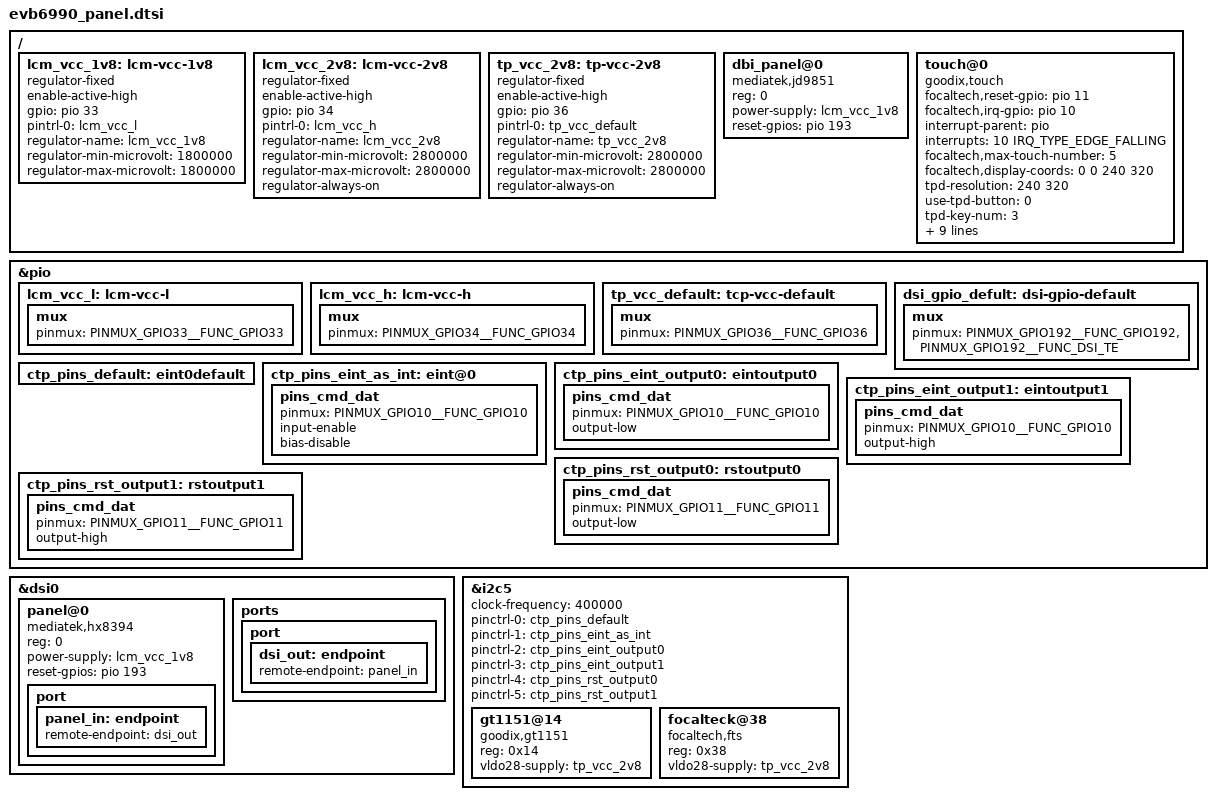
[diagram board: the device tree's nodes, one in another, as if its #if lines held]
/*evb6990_panel.dtsi*/

/ {
	lcm_vcc_1v8: lcm-vcc-1v8 {
        	compatible = "regulator-fixed";
        	enable-active-high;
        	gpio = <&pio 33 GPIO_ACTIVE_HIGH>;
        	pinctrl-names = "default";
        	pintrl-0 = <&lcm_vcc_l>;
        	regulator-name = "lcm_vcc_1v8";
        	regulator-min-microvolt = <1800000>;
        	regulator-max-microvolt = <1800000>;
	};
	
	lcm_vcc_2v8: lcm-vcc-2v8 {
                compatible = "regulator-fixed";
                enable-active-high;
                gpio = <&pio 34 GPIO_ACTIVE_HIGH>;
                pinctrl-names = "default";
                pintrl-0 = <&lcm_vcc_h>;
                regulator-name = "lcm_vcc_2v8";
                regulator-min-microvolt = <2800000>;
                regulator-max-microvolt = <2800000>;
		regulator-always-on;
        };

	tp_vcc_2v8: tp-vcc-2v8 {
                compatible = "regulator-fixed";
                enable-active-high;
                gpio = <&pio 36 GPIO_ACTIVE_HIGH>;
                pinctrl-names = "default";
                pintrl-0 = <&tp_vcc_default>;
                regulator-name = "tp_vcc_2v8";
                regulator-min-microvolt = <2800000>;
                regulator-max-microvolt = <2800000>;
                regulator-always-on;
        };

	dbi_panel@0 {
                compatible = "mediatek,jd9851";
                reg = <0>;
                power-supply = <&lcm_vcc_1v8>;
                //pm-enable-gpios = <&pio 104 1>;
                reset-gpios = <&pio 193 0>;
#ifdef CONFIG_DRM_PANEL_JD9851_DBI_C_4WIRE
                status = "okay";
#else
                status = "disable";
#endif
        };

	touch@0{
#ifdef CONFIG_TOUCHSCREEN_MTK_GT1151
	    	compatible = "goodix,touch";
#elif  CONFIG_TOUCHSCREEN_FTS  
            compatible = "mediatek,touch";   
#endif
            focaltech,reset-gpio = <&pio 11 0>;
            focaltech,irq-gpio = <&pio 10 0>;
            interrupt-parent = <&pio>;
            interrupts = <10 IRQ_TYPE_EDGE_FALLING>;
            focaltech,max-touch-number = <5>;
            focaltech,display-coords =  <0 0 240 320>;

#ifdef CONFIG_DRM_PANEL_JD9851_DBI_C_4WIRE           
            tpd-resolution = <240 320>; // resolution    
#else
            tpd-resolution = <720 1280>; // resolution
#endif
            use-tpd-button = <0>; // if has key(s)
            tpd-key-num = <3>; // key number
            // key codes: KEY_MENU, KEY_HOMEPAGE,KEY_BACK
            // you can find the definition in dts/include/dt-bindings/input/input.h
            tpd-key-local= <139 172 158 0>;
            // rectangle region for keys (center-point x,center-point y, width, height)
            tpd-key-dim-local = <200 2000 100 40 515 2000 100 40 800 2000 100 40 0 0 0 0>;
            tpd-max-touch-num = <5>;
            tpd-filter-enable = <0>;
            tpd-filter-pixel-density = <192>;
            tpd-filter-custom-prameters = <0 0 0 0 0 0 0 0 0 0 0 0>;
            tpd-filter-custom-speed = <0 0 0>;
        };
};

&pio{

	lcm_vcc_l: lcm-vcc-l {
                mux {
                        pinmux = <PINMUX_GPIO33__FUNC_GPIO33>;
                };
        };

	lcm_vcc_h: lcm-vcc-h {
			mux {
					pinmux = <PINMUX_GPIO34__FUNC_GPIO34>;
			};
	};

	tp_vcc_default: tcp-vcc-default {
		mux {
			pinmux = <PINMUX_GPIO36__FUNC_GPIO36>;
		};
	};

	dsi_gpio_defult: dsi-gpio-default{
		mux {
			pinmux = <PINMUX_GPIO192__FUNC_GPIO192>,
					 <PINMUX_GPIO192__FUNC_DSI_TE>;
		};
	};

        
	ctp_pins_default: eint0default {
	};
	ctp_pins_eint_as_int: eint@0 {
			pins_cmd_dat {
					pinmux = <PINMUX_GPIO10__FUNC_GPIO10>;
					input-enable;
					bias-disable;
			};
	};
	ctp_pins_eint_output0: eintoutput0 {
			pins_cmd_dat {
					pinmux = <PINMUX_GPIO10__FUNC_GPIO10>;
					output-low;
			};
	};
	ctp_pins_eint_output1: eintoutput1 {
			pins_cmd_dat {
					pinmux = <PINMUX_GPIO10__FUNC_GPIO10>;
					output-high;
			};
	};
	ctp_pins_rst_output0: rstoutput0 {
			pins_cmd_dat {
					pinmux = <PINMUX_GPIO11__FUNC_GPIO11>;
					output-low;
			};
	};
	ctp_pins_rst_output1: rstoutput1 {
			pins_cmd_dat {
					pinmux = <PINMUX_GPIO11__FUNC_GPIO11>;
					output-high;
			};
	};

};

&dsi0 {
 	status = "okay";
 	#address-cells = <1>;
 	#size-cells = <0>;
 	panel@0 {
                status = "okay"; 
#ifdef  CONFIG_DRM_PANEL_HX8394
 		compatible = "mediatek,hx8394";                 
#elif   CONFIG_DRM_PANEL_ILITEK_ILI9881D
        compatible = "ilitek,ili9881d";
#endif
 		reg = <0>;
		power-supply = <&lcm_vcc_1v8>;
 		reset-gpios = <&pio 193 0>;
 		pinctrl-names = "default";
		//pinctrl-0 = <&dsi_gpio_default>;
 		port {
 			panel_in: endpoint {
 				remote-endpoint = <&dsi_out>;
 			};
 		};
 	};
 	ports {
 		port {
 			dsi_out: endpoint {
 				remote-endpoint = <&panel_in>;
 			};
 		};
 	};
};

&i2c5 {
    status = "okay";
    clock-frequency = <400000>;

	pinctrl-names = "default", "state_eint_as_int",
                "state_eint_output0","state_eint_output1",
                "state_rst_output0", "state_rst_output1";
    pinctrl-0 = <&ctp_pins_default>;
    pinctrl-1 = <&ctp_pins_eint_as_int>;
    pinctrl-2 = <&ctp_pins_eint_output0>;
    pinctrl-3 = <&ctp_pins_eint_output1>;
    pinctrl-4 = <&ctp_pins_rst_output0>;
    pinctrl-5 = <&ctp_pins_rst_output1>;

    gt1151@14 {
        compatible = "goodix,gt1151";
        reg = <0x14>;
        vldo28-supply = <&tp_vcc_2v8>;
#ifdef CONFIG_TOUCHSCREEN_MTK_GT1151
        status = "okay";
#else
        status = "disable";
#endif
    };

    focalteck@38 {
        compatible = "focaltech,fts";
        reg = <0x38>;
        vldo28-supply = <&tp_vcc_2v8>;
#ifdef CONFIG_TOUCHSCREEN_FTS
	status = "okay";
#else
        status = "disable";
#endif
    };
};
